# USB0_COMMON_0_VBP2APB_WRAP_CONTROLLER_VBP_CORE_ADDR_MAP register map
Vendor: Texas Instruments
Registers are 32-bit, access per field, reset 0x0 unless marked. A register's access mark holds for its fields unless they carry their own. Offsets are as the file gives them; [hi:lo] are bit positions; {n}, {i} and the like mark numbered series; 'fields as' and 'values as' point back to an identical list.

## USB0_COMMON_0_VBP2APB_WRAP_CONTROLLER_VBP_CORE_ADDR_MAP (part 8 of 8)
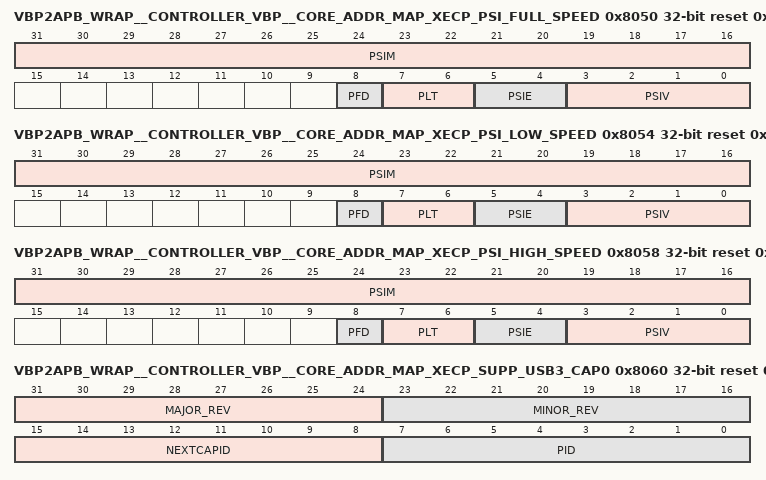
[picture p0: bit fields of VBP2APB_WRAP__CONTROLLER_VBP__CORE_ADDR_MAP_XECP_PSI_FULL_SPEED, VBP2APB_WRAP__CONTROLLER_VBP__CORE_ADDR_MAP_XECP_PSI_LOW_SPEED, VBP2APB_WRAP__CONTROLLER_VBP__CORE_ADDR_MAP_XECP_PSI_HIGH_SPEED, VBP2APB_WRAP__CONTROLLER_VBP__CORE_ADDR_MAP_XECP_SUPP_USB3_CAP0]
0x8050 VBP2APB_WRAP__CONTROLLER_VBP__CORE_ADDR_MAP_XECP_PSI_FULL_SPEED ro reset 0xC0021
  [31:16] PSIM — Protocol Speed ID Mantissa. This field defines the mantissa that shall be applied to the PSIE when calculating the maximum bit rate represented by this PSI Dword.
  [8] PFD — PSI Full-duplex. If this bit is '1' the link is full-duplex, and if '0' the link is half-duplex.
  [7:6] PLT — PSI Type. This field identifies whether the PSI Dword defines a symmetric or asymmetric bit rate, and if asymmetric, then this field also indicates if this Dword defines the receive or transmit bit rate. Note that the Asymmetric PSI Dwords shall be paired, i.e. an Rx immediately followed by a Tx, and both Dwords shall define the same value for the PSIV. PLT Values and corresponding bit rate: 0: Symmetric [Single PSI Dword] 1: Reserved 2: Asymmetric Rx [Paired with Asymmetric Tx PSI Dword] 3: Asymmetric Tx [Immediately follows Rx Asymmetric PSI Dword].
  [5:4] PSIE — Protocol Speed ID Exponent. This field defines the base 10 exponent times 3, that shall be applied to the Protocol Speed ID Mantissa when calculating the maximum bit rate represented by this PSI Dword. PSIE Values and corresponding bit rates: 0: Bits per second 1: Kb/s 2: Mb/s 3: Gb/s .
  [3:0] PSIV — Protocol Speed ID Value. If a device is attached that operates at the bit rate defined by this PSI Dword, then the value of this field shall be reported in the Port Speed field of PORTSC register [5.4.8 of xHCI specification] of a compatible port. Note, the PSIV value of 0 is reserved and shall not be defined by a PSI.
0x8054 VBP2APB_WRAP__CONTROLLER_VBP__CORE_ADDR_MAP_XECP_PSI_LOW_SPEED ro reset 0x5DC0012
  [31:16] PSIM — Protocol Speed ID Mantissa. This field defines the mantissa that shall be applied to the PSIE when calculating the maximum bit rate represented by this PSI Dword.
  [8] PFD — PSI Full-duplex. If this bit is '1' the link is full-duplex, and if '0' the link is half-duplex.
  [7:6] PLT — PSI Type. This field identifies whether the PSI Dword defines a symmetric or asymmetric bit rate, and if asymmetric, then this field also indicates if this Dword defines the receive or transmit bit rate. Note that the Asymmetric PSI Dwords shall be paired, i.e. an Rx immediately followed by a Tx, and both Dwords shall define the same value for the PSIV. PLT Values and corresponding bit rate: 0: Symmetric Single [PSI Dword] 1: Reserved 2: Asymmetric Rx [Paired with Asymmetric Tx PSI Dword] 3: Asymmetric Tx [Immediately follows Rx Asymmetric PSI Dword].
  [5:4] PSIE — Protocol Speed ID Exponent. This field defines the base 10 exponent times 3, that shall be applied to the Protocol Speed ID Mantissa when calculating the maximum bit rate represented by this PSI Dword. PSIE Values and corresponding bit rates: 0: Bits per second 1: Kb/s 2: Mb/s 3: Gb/s .
  [3:0] PSIV — Protocol Speed ID Value. If a device is attached that operates at the bit rate defined by this PSI Dword, then the value of this field shall be reported in the Port Speed field of PORTSC register [5.4.8 of xHCI specification] of a compatible port. Note, the PSIV value of 0 is reserved and shall not be defined by a PSI.
0x8058 VBP2APB_WRAP__CONTROLLER_VBP__CORE_ADDR_MAP_XECP_PSI_HIGH_SPEED ro reset 0x1E00023
  fields as VBP2APB_WRAP__CONTROLLER_VBP__CORE_ADDR_MAP_XECP_PSI_LOW_SPEED
0x8060 VBP2APB_WRAP__CONTROLLER_VBP__CORE_ADDR_MAP_XECP_SUPP_USB3_CAP0 ro reset 0x3000802
  [31:24] MAJOR_REV — Major Specification Release Number in Binary-Coded Decimal [i.e.,version 3.x is 03h]. This field identifies the major release number component of the specification with which the xHC is compliant.
  [23:16] MINOR_REV — Minor Specification Release Number in Binary-Coded Decimal [i.e.,version x.10 is 10h]. This field identifies the minor release number component of the specification with which the xHC is compliant.
  [15:8] NEXTCAPID — This field indicates the location of the next capability with respect to the effective address of this capability. Refer to Table 142 of xHCI specification for more information on this field.
  [7:0] PID — Capability ID. The value identifies the capability as Supported Protocol.
0x8064 VBP2APB_WRAP__CONTROLLER_VBP__CORE_ADDR_MAP_XECP_SUPP_USB3_CAP1 ro reset 0x20425355
  [31:0] USB_STRING — Name String, RO. This field is a mnemonic name string that references the specification with which the xHC is compliant. Four ASCII characters may be defined. Allowed characters are: alphanumeric, space, and underscore. Alpha characters are case sensitive. Refer to section 7.2.2 of xHCI specification for defined values.
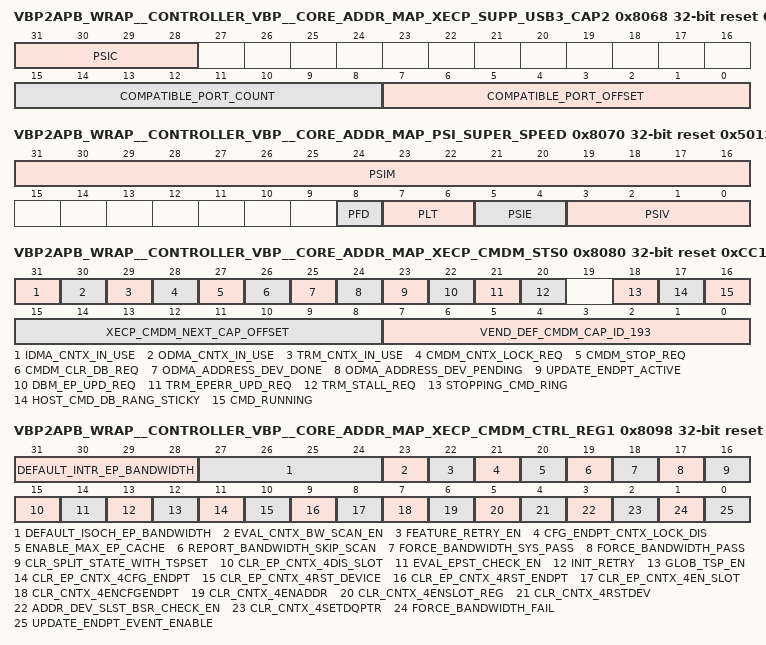
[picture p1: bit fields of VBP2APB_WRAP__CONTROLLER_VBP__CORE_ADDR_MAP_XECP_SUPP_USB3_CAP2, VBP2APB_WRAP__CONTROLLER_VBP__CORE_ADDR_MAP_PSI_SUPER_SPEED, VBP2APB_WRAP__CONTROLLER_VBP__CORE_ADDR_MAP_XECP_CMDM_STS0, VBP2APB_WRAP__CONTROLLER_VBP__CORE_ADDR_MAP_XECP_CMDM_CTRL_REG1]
0x8068 VBP2APB_WRAP__CONTROLLER_VBP__CORE_ADDR_MAP_XECP_SUPP_USB3_CAP2 ro reset 0x10000102
  [31:28] PSIC — Protocol Speed ID CountCount : 1, USB 3.0 Speed [Super Speed]. This field indicates the number of Protocol Speed ID [PSI] Dwords that the xHCI Supported Protocol Capability data structure contains. If this field is non-zero, then all speeds supported by the protocol shall be defined using PSI Dwords, i.e. no implied Speed ID mappings apply.
  [15:8] COMPATIBLE_PORT_COUNT — This field identifies the number of consecutive Root Hub Ports [starting at the Compatible Port Offset] that support this protocol. Valid values are 1 to MaxPorts.
  [7:0] COMPATIBLE_PORT_OFFSET — This field specifies the starting Port Number of Root Hub Ports that support this protocol. Valid values are 1 to MaxPorts.
0x806C VBP2APB_WRAP__CONTROLLER_VBP__CORE_ADDR_MAP_XECP_SUPP_USB3_PROTOCOL_SLOT_TYPE ro
  [4:0] PST — This field specifies the Protocol Slot Type value, which may be specified when allocating Device Slots that support this protocol. Valid values are 0 to 31. Refer to sections 4.6.3 and 7.2.2.1.4 of xHCI specification. The value of the Protocol Slot Type field declared by a xHCI Supported Protocol Capability structure is unique to an xHC implementation. Software shall not assume a fixed mapping of the Protocol Slot Type value to a specific type of Supported Protocol. Note that for compatibility reasons, the Protocol Slot Type value of 0 is the exception to this rule and reserved for the USB Protocol Device Slot type.
0x8070 VBP2APB_WRAP__CONTROLLER_VBP__CORE_ADDR_MAP_PSI_SUPER_SPEED ro reset 0x50134
  fields as VBP2APB_WRAP__CONTROLLER_VBP__CORE_ADDR_MAP_XECP_PSI_LOW_SPEED
0x8080 VBP2APB_WRAP__CONTROLLER_VBP__CORE_ADDR_MAP_XECP_CMDM_STS0 ro reset 0xCC1
  [31] IDMA_CNTX_IN_USE — Indicates that IDMA module currently owns the context access :
  [30] ODMA_CNTX_IN_USE — Indicates that ODMA module currently owns currently the context access
  [29] TRM_CNTX_IN_USE — Indicates that TRM modules owns the context access currently
  [28] CMDM_CNTX_LOCK_REQ — Indicates that Command Manager has requested a context lock.
  [27] CMDM_STOP_REQ — Indicates that Command Ring stop command is in progress.
  [26] CMDM_CLR_DB_REQ — Indicates that clearing an EP out of schedule is in progress.
  [25] ODMA_ADDRESS_DEV_DONE — Indicates that current address device command is done by ODMA.
  [24] ODMA_ADDRESS_DEV_PENDING — Indicates that ODMA has an address device command in progress.
  [23] UPDATE_ENDPT_ACTIVE — Indicates that updating of EP state is in progress
  [22] DBM_EP_UPD_REQ — Indicates that Doorbell Manager is issuing and EP update due to a doorbell ring on an EP that is in stop state
  [21] TRM_EPERR_UPD_REQ — Indicates that Transfer Ring Manager is issuing and EP update due to an EP error condition detected
  [20] TRM_STALL_REQ — Indicates that transfer ring manager is issuing and EP state update due to stall received
  [18] STOPPING_CMD_RING — Indicates that a STOP on the Command Ring is in progress
  [17] HOST_CMD_DB_RANG_STICKY — Indicates that command ring has a doorbell pending
  [16] CMD_RUNNING — Indicates that the command ring is running
  [15:8] XECP_CMDM_NEXT_CAP_OFFSET — Next capability offset
  [7:0] VEND_DEF_CMDM_CAP_ID_193 — Vendor defined capability ID. Command Ring Manager capability ID.
{0x8080+4i} VBP2APB_WRAP__CONTROLLER_VBP__CORE_ADDR_MAP_XECP_CMDM_RESERVED_{i} ro (i=1..5)
0x8098 VBP2APB_WRAP__CONTROLLER_VBP__CORE_ADDR_MAP_XECP_CMDM_CTRL_REG1 rw reset 0x3580AFFC
  [31:28] DEFAULT_INTR_EP_BANDWIDTH — Bandwidth calculation parameter: Default bandwidth for an Interrupt Endpoint.
  [27:24] DEFAULT_ISOCH_EP_BANDWIDTH — Bandwidth calculation parameter: Default bandwidth for an Isochronous Endpoint.
  [23] EVAL_CNTX_BW_SCAN_EN — Enable the Host Controller's Bandwidth checks for the Evaluate Context Command. Rescan the BW during evaluate context
  [22] FEATURE_RETRY_EN — Enable the EOB and NPKT==0 [called NYET condition for USB3] to be used to update a retry bit during stream switching operation. This is an internal safety feature. It should be treated as reserved bit.
  [21] CFG_ENDPT_CNTX_LOCK_DIS — Context lock mechanism to ensure command manager has exclusive access to internal context. This is a disable bit to allow software to turn off the context lock for configure endpoint command. This is a test/debug feature. '1': indicates disabled. '0': Indicates enabled
  [20] ENABLE_MAX_EP_CACHE
  [19] REPORT_BANDWIDTH_SKIP_SCAN
  [18] FORCE_BANDWIDTH_SYS_PASS
  [17] FORCE_BANDWIDTH_PASS
  [16] CLR_SPLIT_STATE_WITH_TSPSET — This bit allows engine to reset the split states when reset endpoint with TSP is posted. The split state is an internal context field in DMA engine. '0': Indicates that reset endpoint with TSP will preserve the split state. '1': Indicates that the reset endpoint with TSP will not preserve the split state.
  [15] CLR_EP_CNTX_4DIS_SLOT — '0': Disable clearing internal TRM and DMA context as well as the internal EP status signals during a disable slot command. '1': Enable clearing internal TRM and DMA context as well as the internal EP status signals during a disable slot command.
  [14] EVAL_EPST_CHECK_EN — '0': Disable evaluating the endpoint state during an Evaluate Context command, '1': Enable EP state check during an Evaluate Context command. If failed, context error will be returned.
  [13] INIT_RETRY — init_retry. Reserved to always read value of '1'.
  [12] GLOB_TSP_EN — '0': Disable the global context preservation. '1': Enable the internal context preservation for all commands that needs to preserve some of the internal context fields as a command with TSP would.
  [11] CLR_EP_CNTX_4CFG_ENDPT — '0': Disable clearing other internal EP status signals during a configure endpoint command. '1': Enable clearing other internal EP related status signals such as EP scheduled array, credit stored per EP, etc. during a configure endpoint command.
  [10] CLR_EP_CNTX_4RST_DEVICE — '0': Disable clearing other internal EP status signals during a reset device command. '1': Enable clearing other internal EP related status signals such as EP scheduled array, credit stored per EP, etc. during a reset device command.
  [9] CLR_EP_CNTX_4RST_ENDPT — '0': Disable clearing other internal EP status signals during a reset endpoint command. '1': Enable clearing other internal EP related status signals such as EP scheduled array, credit stored per EP. etc. during a reset endpoint command.
  [8] CLR_EP_CNTX_4EN_SLOT — '0': Disable clearing other internal EP status signals during an enable slot command. '1': Enable clearing other internal EP related status signals such as EP scheduled array, credit stored per EP. etc., during an enable slot command.
  [7] CLR_CNTX_4ENCFGENDPT — '0': Disable clearing internal TRM and DMA context during a configure endpoint command. '1': Enable clearing internal TRM and DMA context during a configure endpoint command.
  [6] CLR_CNTX_4ENADDR — '0': Disable clearing internal TRM and DMA context during an address device command. '1': Enable clearing internal TRM and DMA context during an address device command.
  [5] CLR_CNTX_4ENSLOT_REG — '0': Disable clearing internal TRM and DMA context during an enable slot command. '1': Enable clearing internal TRM and DMA context during an enable slot command.
  [4] CLR_CNTX_4RSTDEV — '0': Disable clearing internal TRM and DMA context during a reset device command. '1': Enable clearing internal TRM and DMA context during a reset device command.
  [3] ADDR_DEV_SLST_BSR_CHECK_EN — '0': Address device does not return the error for this condition. '1': Enable the EP state [default state] check with address device command with BSR. If failed, an event with context state error will be generated.
  [2] CLR_CNTX_4SETDQPTR — '0': Disable clearing internal TRM and DMA context during a set TR DQ pointer command. '1': Enable clearing internal TRM and DMA context during a set TR DQ pointer command.
  [1] FORCE_BANDWIDTH_FAIL — '0': Bandwidth calculation handled normally. '1': Forces a failure in the endpoint bandwidth calculation so that engine will reject a configure EP command.
  [0] UPDATE_ENDPT_EVENT_ENABLE — '0': Disable generation of the completion event. '1': Enable the command manager to generate a completion event after an EP state update due to internal error. This bit is for test debug.
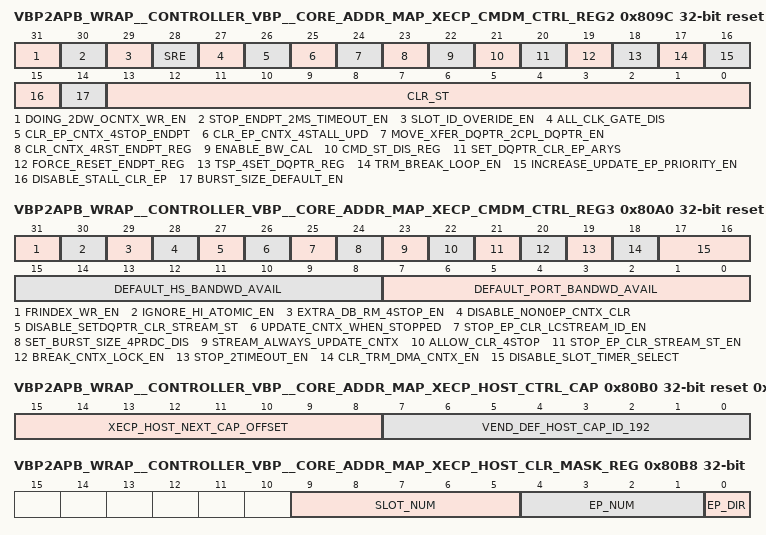
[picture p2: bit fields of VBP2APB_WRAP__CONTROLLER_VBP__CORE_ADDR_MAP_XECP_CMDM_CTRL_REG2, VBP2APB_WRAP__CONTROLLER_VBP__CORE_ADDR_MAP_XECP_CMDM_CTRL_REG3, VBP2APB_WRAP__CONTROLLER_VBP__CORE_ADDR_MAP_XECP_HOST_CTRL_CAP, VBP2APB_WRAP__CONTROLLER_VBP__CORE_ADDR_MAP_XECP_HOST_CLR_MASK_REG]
0x809C VBP2APB_WRAP__CONTROLLER_VBP__CORE_ADDR_MAP_XECP_CMDM_CTRL_REG2 rw reset 0x6C60000
  [31] DOING_2DW_OCNTX_WR_EN — Enable only to update the EP state to output context on every EP output context update condition. This is to allow to have a control over either update the entire EPoutput context field or only update the first two DWORDs. '0': update the entire output context field. '1': update only 2 DWORDs
  [30] STOP_ENDPT_2MS_TIMEOUT_EN — Enable a delay to stop endpoint command that is executed in XFER engine. '0': XFER engine will not wait. '1': XFER engine will always wait for 2 ms before it checks whether an EP transfer ring is at a stop of packet boundary
  [29] SLOT_ID_OVERIDE_EN — Force '0' on slot ID when a command transfer event is generated. '0': not forced, '1': Forced to 0.
  [28] SRE — Force and error on save command always. '0': do not force, '1': always force return save error.
  [27] ALL_CLK_GATE_DIS — '0': Turn ON the TTE clock. '1': Turn OFF the TTE clock.
  [26] CLR_EP_CNTX_4STOP_ENDPT — '0': Disable clearing other internal per EP status signal during a stop endpoint command. '1': Enable clearing other internal per EP status signal during a stop endpoint command.
  [25] CLR_EP_CNTX_4STALL_UPD — '0': Disable clearing other internal EP status signal during stall handling. '1': Enable clearing other internal EP status signal during stall handling.
  [24] MOVE_XFER_DQPTR_2CPL_DQPTR_EN — '0': The internal context write DQ pointer moved to internal read pointer during reset EP command. '1': The write DQ pointer stays as it was during reset endpoint command.
  [23] CLR_CNTX_4RST_ENDPT_REG — '0': Disable clearing internal TRM and DMA context during a reset endpoint command. '1': Enable clearing internal TRM and DMA context during a reset endpoint command.
  [22] ENABLE_BW_CAL — '0': Disable hardware bandwidth calculations. '1': Enable hardware bandwidth calculations.
  [21] CMD_ST_DIS_REG — '0': Delay processing command ring TRB while internal context requests are pending. '1': Process command ring TRBs normally.
  [20] SET_DQPTR_CLR_EP_ARYS — '0': Disable clearing other internal EP status signals during a set DQ pointer command. '1': Enable clearing other internal EP status signals during a set DQ pointer command.
  [19] FORCE_RESET_ENDPT_REG — '0': Check the slot and endpoint state prior to processing a reset endpoint command. '1': Ignore the slot and endpoint state when processing a reset endpoint command.
  [18] TSP_4SET_DQPTR_REG — '0': Disable sequence number preservation during set DQ pointer command. '1': Enable sequence number to be preserved during set DQ pointer command.
  [17] TRM_BREAK_LOOP_EN — trm_break_loop_en. This is an internal safeguard register. It enables a different mechanism of handling stop endpoint command. It should be treated as a reserved field. The default should not be alternate unless specific purpose. '0': Disable. '1': Enable.
  [16] INCREASE_UPDATE_EP_PRIORITY_EN — Increase Update EP priority over commands in the command ring to avoid prolonging STALL handling. '0': Pending commands have a higher priority than update endpoint processing. '1': Update endpoint processing in the command manager has a higher priority than pending commands. Note: Enabling this bit can prevent prolonged stall handling.
  [15] DISABLE_STALL_CLR_EP — '0': Stall handling does clear the internal EP status signals. '1': Disable the clear function when stall response received.
  [14] BURST_SIZE_DEFAULT_EN — When context is first initialized, it is assumed one remote NPKT. It is also assumed that max burst size as remote NPKT. This bit enables to assume max burst size as remote NPKT. '0': Assume 1 NPKT. '1': Assume max burst size as NPKT.
  [13:0] CLR_ST — Clear state machine present state: Setting a specified bit to '1', will reset the corresponding command manager state machine to the starting/idle state. bit-0: disable slot state machine. bit-1: enable slot state machine. bit-2: reset endpoint state machine. bit-3: reset device state machine. bit-4: command ring state machine. bit-5: stop endpoint state machine. bit-6: set dq pointer state machine. bit-7: force header state machine. bit-8: evaluate context state machine. bit-9: update endpoint state machine. bit-10: address device state machine. bit-11: port bandwidth state machine. bit-12: read output context state machine. bit-13: configure endpoint state machine.
0x80A0 VBP2APB_WRAP__CONTROLLER_VBP__CORE_ADDR_MAP_XECP_CMDM_CTRL_REG3 rw reset 0x2220505A
  [31] FRINDEX_WR_EN — MFIndex register write enable. For debug purposes.
  [30] IGNORE_HI_ATOMIC_EN
  [29] EXTRA_DB_RM_4STOP_EN
  [28] DISABLE_NON0EP_CNTX_CLR
  [27] DISABLE_SETDQPTR_CLR_STREAM_ST — disable_setdqptr_clr_stream_st. Disable setTRDQPtr from clearing the current stream state.
  [26] UPDATE_CNTX_WHEN_STOPPED — update_cntx_when_stopped. Allow setTRDQPtr cmd to update the local context anytime the EP is not running [otherwise checks CSTREAMID].
  [25] STOP_EP_CLR_LCSTREAM_ID_EN — stop_ep_clr_lcstream_id_en. Enable stop endpoint command to return stream st to disabled [0] in EP context.
  [24] SET_BURST_SIZE_4PRDC_DIS
  [23] STREAM_ALWAYS_UPDATE_CNTX
  [22] ALLOW_CLR_4STOP
  [21] STOP_EP_CLR_STREAM_ST_EN — stop_ep_clr_stream_st_en. Enable stop endpoint command to return stream st to disabled [0] in EP context.
  [20] BREAK_CNTX_LOCK_EN
  [19] STOP_2TIMEOUT_EN — stop_2timeout_en. Stop transaction timeout.
  [18] CLR_TRM_DMA_CNTX_EN
  [17:16] DISABLE_SLOT_TIMER_SELECT — These two bits specify the delay that we can have for disable slot state to be completed. We can delay the generation of the command transfer event during disable slot command. Possible values: '00': delay is disabled, '01': 100us delay, '10': 8ms delay, '11': 10ms delay.
  [15:8] DEFAULT_HS_BANDWD_AVAIL — The default available bandwidth to advertise on each HS port in 10 0ncrements [80%]. Bandwidth Calculation is a reserved field for PPT.
  [7:0] DEFAULT_PORT_BANDWD_AVAIL — The default available bandwidth to advertise on each LS, FS, SS port in 10 0ncrements [90%]. Bandwidth calculation is a reserved field for PPT.
0x80B0 VBP2APB_WRAP__CONTROLLER_VBP__CORE_ADDR_MAP_XECP_HOST_CTRL_CAP ro reset 0xB0C0
  [15:8] XECP_HOST_NEXT_CAP_OFFSET — Next xHCI Extended Capability Pointer. This field points to the xHC MMIO space offset of the next xHCI extended capability pointer. A value of 00h indicates the end of the extended capability list. A non-zero value in this register indicates a relative offset, in Dwords, from this Dword to the beginning of the next extended capability. For example, assuming an effective address of this data structure is 350h and assuming a pointer value of 068h, we can calculate the following effective address: 350h + [068h shifted left 2] -> 350h + 1A0h -> 4F0h
  [7:0] VEND_DEF_HOST_CAP_ID_192 — Capability ID. This field identifies the xHCI Extended capability. 192-255 are IDs available for vendor specific extensions to the xHCI.
0x80B4 VBP2APB_WRAP__CONTROLLER_VBP__CORE_ADDR_MAP_XECP_HOST_CTRL_RSVD ro
0x80B8 VBP2APB_WRAP__CONTROLLER_VBP__CORE_ADDR_MAP_XECP_HOST_CLR_MASK_REG
  [9:5] SLOT_NUM wo — Slot number.
  [4:1] EP_NUM wo — Endpoint number
  [0] EP_DIR wo — Indicates the direction of the Endpoint
0x80BC VBP2APB_WRAP__CONTROLLER_VBP__CORE_ADDR_MAP_XECP_HOST_CLR_IN_EP_VALID_REG wo
  [31:0] PORT_NUM — This field indicates the port number.
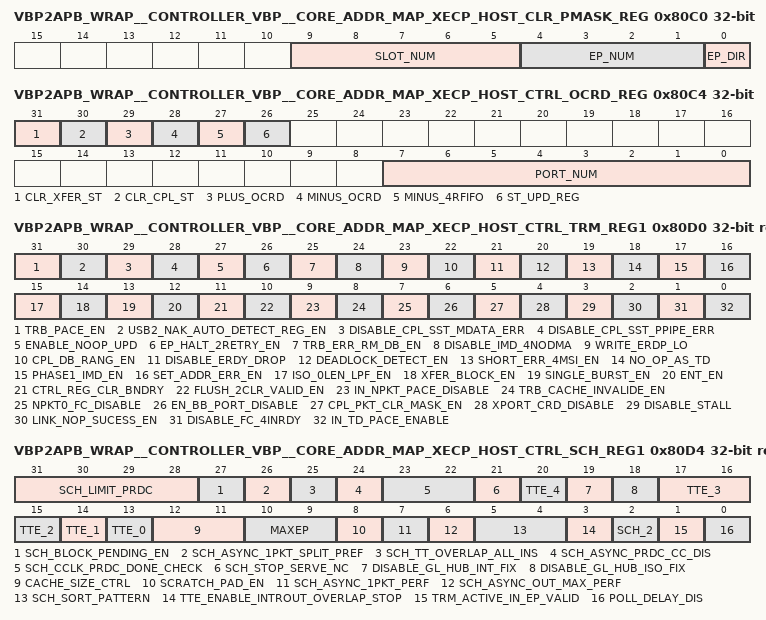
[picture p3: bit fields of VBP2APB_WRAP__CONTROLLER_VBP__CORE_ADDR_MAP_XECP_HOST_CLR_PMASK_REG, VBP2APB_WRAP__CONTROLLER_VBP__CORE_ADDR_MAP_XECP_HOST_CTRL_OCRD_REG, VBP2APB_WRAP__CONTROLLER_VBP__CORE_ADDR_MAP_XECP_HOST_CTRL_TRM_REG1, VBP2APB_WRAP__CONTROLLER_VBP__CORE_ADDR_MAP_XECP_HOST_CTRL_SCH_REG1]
0x80C0 VBP2APB_WRAP__CONTROLLER_VBP__CORE_ADDR_MAP_XECP_HOST_CLR_PMASK_REG
  [9:5] SLOT_NUM wo — Slot number
  [4:1] EP_NUM wo — Endpoint number
  [0] EP_DIR wo — Indicates the direction of the Endpoint
0x80C4 VBP2APB_WRAP__CONTROLLER_VBP__CORE_ADDR_MAP_XECP_HOST_CTRL_OCRD_REG
  [31] CLR_XFER_ST wo — Write '1' to force XFER state return to IDLE
  [30] CLR_CPL_ST wo — Write '1' to force CPL state return to IDLE
  [29] PLUS_OCRD wo — Add one credit to a port
  [28] MINUS_OCRD wo — Subtract one credit from a port
  [27] MINUS_4RFIFO wo — Indicates whether the subtract command operates on TX FIFO credit or RX FIFO credit.
  [26] ST_UPD_REG ro — Slot state control. st_upd_reg
  [7:0] PORT_NUM wo — port number
0x80C8 VBP2APB_WRAP__CONTROLLER_VBP__CORE_ADDR_MAP_XECP_HOST_CTRL_TEST_BUS_LO ro
  [31:0] TEST_BUS_LO — Host controller test bus low 32-bits.
0x80CC VBP2APB_WRAP__CONTROLLER_VBP__CORE_ADDR_MAP_XECP_HOST_CTRL_TEST_BUS_HI ro
  [31:0] TEST_BUS_HI — Host controller test bus high 32-bits.
0x80D0 VBP2APB_WRAP__CONTROLLER_VBP__CORE_ADDR_MAP_XECP_HOST_CTRL_TRM_REG1 rw reset 0x4E1BD105
  [31] TRB_PACE_EN — Must be set to '0'.
  [30] USB2_NAK_AUTO_DETECT_REG_EN — '0': Disables a special function which detects NAK received and goes into a single packet pace mode so that we do not burst ahead. '1': Enables a special function which detects NAK received and goes into a single packet pace mode so that we do not burst ahead.
  [29] DISABLE_CPL_SST_MDATA_ERR — '0': Enable the error check. '1': Disable the error check for Data Move stream state. It will generate a transfer event with prime PIPE error completion code if an error is detected.
  [28] DISABLE_CPL_SST_PPIPE_ERR — '0': Enable the error check, '1': Disable the error check for prime PIPE stream state. It will generate a transfer event with prime PIPE error completion code if an error is detected.
  [27] ENABLE_NOOP_UPD — This bit has been modified for its usage since PPT A0. It is used to allow NO-OP TRB to be treated in a same way as link TRB. In other words, it will update the internal context when it is fetched while the internal context cache TRB FIFO is empty. '0': Disable the function, '1': Enable the cache function.
  [26] EP_HALT_2RETRY_EN — This is a special internal condition enable for CPL engine which it enables all EP halt conditions detected to cause the proper actions in a response. '0': Disabled, '1': Enabled. Note: Only default condition of '1' is valid.
  [25] TRB_ERR_RM_DB_EN — This is a special internal branch condition control in XFER engine which does the EP transfer ring process. When this bit is set a retry condition identified by completion engine will cause XFER engine to stop what it is currently in progress and start over from IDLE state. '0': Disable, '1': Enable the branch condition.
  [24] DISABLE_IMD_4NODMA — This is a special internal branch condition control in XFER engine which does the EP transfer ring process. When this bit is set, the XFER will not continue even if the next TRB is identified as a non DMA TRB. The engine will then wait for the next scheduled request for this EP. '0': Disable, '1': Enable the branch condition.
  [23] WRITE_ERDP_LO — When ERDP register is updated by software, it is expected as an atomic function since this is a 64-bit register. It is expected, that the ERDP [64-bit register] is updated together when ERDP high 32 is written. We have this bit designed to ignore the atomic operation required from software for ERDP low 32 bits. When this bit is set to '1', it will update the ERDP low 32 bits when software issues a CPU write to the ERDP low 32 bits. '0': not ignore, '1': ignore atomic operation.
  [22] CPL_DB_RANG_EN — Setting this bit to '1' will force an internal doorbell ring on the EP that it has received a response.
  [21] DISABLE_ERDY_DROP — '0': Drop ERDYs received when not in a flow control state. '1': Do not drop ERDYs received when not in a flow control state. Note: We typically drop unexpected ERDY
  [20] DEADLOCK_DETECT_EN — '0': Disable timeout of TRB error processing. '1': Enable timeout of a TRB processing in few critical states that possibly have a deadlock for unexpected reason. A vendor defined completion code is generated in the event of a timeout during TRB processing.
  [19] SHORT_ERR_4MSI_EN — This bit is modified to enable a feature where we can control whether or not to report an event with completion code of Missed Service Error when a short packet response has been received not in the expected service interval. '0': Disable this function so that the xHC engine will report an event with completion code of Short packet indication and another event with MSE at the end of the TD, '1': Enables all completion event that supposedly is short to the MSE.
  [18] NO_OP_AS_TD — This bit is modified to enable the NO_OP TRB as a TD when Missing Service Interval Error has encountered. This is only for PPT B0, LPT and CB. '0': disable, '1': enable.
  [17] PHASE1_IMD_EN — Enable a special branch condition of the XFER ring process state. This is to ensure that we have a DMA request issued to DMA engine during a PHASE1 process of the TTE. '0': disabled, '1': enabled
  [16] SET_ADDR_ERR_EN — '0': Disable error reporting if a SETUP TRB contains the following: bRequest = SET_ADDRES, bmRequestType = [DTD] Host-to-device, Type = Standard, Recipient = Device. '1': Enable error reporting for this case.
  [15] ISO_0LEN_LPF_EN — Enables a special internal state branch condition for periodic EP during its transfer ring process. If we have identified that the next TRB is a non DMAnable TRB such as LINK TRB, or Event data TRB, then this bit enables XFER engine to continue process the next TRB as if the ENT bit of the TRB is set. '0': disable, '1': enable.
  [14] XFER_BLOCK_EN — Not used. XFER engine has a new function that provides a support to ISO EP within a long PCIe delayed system. The long delay can cause missing service interval while pending response has not all been returned. This bit enables engine to identify a MSI condition and store the context bit for a pending response so that we can process a MSI event when pending response received. '0': disable this function, '1': enable this function.
  [13] SINGLE_BURST_EN — '0': Bulk and interrupt endpoints use burst size defined by endpoint context. '1: Force the Bulk and Interrupt endpoints to use a burst size of 1.
  [12] ENT_EN — '0': ENT bit is ignored. '1': ENT bit is processed. The transfer engine will service the next TRB.
  [11] CTRL_REG_CLR_BNDRY — Setting this bit to '1' will force the transfer engine to set the packet boundary flag. This flag is an important flag, which may cause a deadlock. This is a safety feature that we have plugged in.
  [10] FLUSH_2CLR_VALID_EN — This bit is modified to support PPTB0, LPT and CP for a feature that we will clear the single IN EP array based on ISO flush or short flush. '0': Indicate that we do not need to clear IN EP array based on flush conditions. '1': indicate that we do clear IN EP array based on flush conditions
  [9] IN_NPKT_PACE_DISABLE — Setting this bit to '1' will force the transfer engine state machine to exit the CPL_WAIT state. This is designed to avoid unexpected deadlock in CPL_WAIT state.
  [8] TRB_CACHE_INVALIDE_EN — '0': Disable internal TRB cache invalidation. '1': Enable internal TRB cache invalidation auto detect function. This will allow engine to handle more than 4 TRBs per packet.
  [7] NPKT0_FC_DISABLE — '0': USB3 responses with NumPkts equal to 0 will be treated as a flow control condition. '1': USB3 responses with NumPkts equal to 0 will not be treated as a flow control condition.
  [6] EN_BB_PORT_DISABLE — '0': Babble errors will not disable the port. '1': Babble errors will disable the auto detect function This will allow engine to handle more than 4 TRBs per packet.
  [5] CPL_PKT_CLR_MASK_EN — Enable a function, which clears a mask of an EP on any response of that EP. '0': Clear the scheduler mask normally, '1': Clear the scheduler mask on each received packet.
  [4] XPORT_CRD_DISABLE — This bit is designed to allow XFER engine to do a transfer without checking against the available port credit. '0': Advertises accurate buffer credit information to the scheduler. '1': Advertises non-zero buffer credits to the scheduler [e.g. never backpressure back on buffer credit information]
  [3] DISABLE_STALL — '0': Process stalls reported by the DMA engine. '1': Ignore stall response received reported by the DMA engine.
  [2] LINK_NOP_SUCESS_EN — '0': Process transaction errors due to CERR count reached or transaction timeout reported by the DMA engine. '1': Ignore transaction errors reported by the DMA engine.
  [1] DISABLE_FC_4INRDY — '0': Obey the NPKT0 and EOB flow control. '1': Ignore received flow control for implied NRDY [e.g EOB or NPKT=0] for USB3 only
  [0] IN_TD_PACE_ENABLE — '0': Disable TD pacing for IN endpoint. '1': Enable TD pacing for IN endpoints.
0x80D4 VBP2APB_WRAP__CONTROLLER_VBP__CORE_ADDR_MAP_XECP_HOST_CTRL_SCH_REG1 rw reset 0x8100
  [31:28] SCH_LIMIT_PRDC — Host Control Scheduler: sch_limit_prdc
  [27] SCH_BLOCK_PENDING_EN — Host Control Scheduler: sch_block_pending_en
  [26] SCH_ASYNC_1PKT_SPLIT_PREF — Host Control Scheduler: sch_async_1pkt_split_pref
  [25] SCH_TT_OVERLAP_ALL_INS — Host Control Scheduler: sch_tt_overlap_all_ins
  [24] SCH_ASYNC_PRDC_CC_DIS — Host Control Scheduler: sch_async_prdc_cc_dis
  [23:22] SCH_CCLK_PRDC_DONE_CHECK — Host Control Scheduler: sch_cclk_prdc_done_check
  [21] SCH_STOP_SERVE_NC — Host Control Scheduler: Enable Stop serving packets to disabled port
  [20] TTE_4 — TTE: Reserved
  [19] DISABLE_GL_HUB_INT_FIX — TTE: disable_gl_hub_int_fix
  [18] DISABLE_GL_HUB_ISO_FIX — TTE: disable_gl_hub_iso_fix
  [17:16] TTE_3 — TTE: Reserved
  [15] TTE_2 — TTE: Disable split error request to TRM on unserved interrupt-INs
  [14] TTE_1 — TTE: Disable checking of missed microframes
  [13] TTE_0 — TTE: Disable interrupt complete split limit to 3 micro frames
  [12:11] CACHE_SIZE_CTRL — Command Manager: Context cache enable
  [10:9] MAXEP — Command Manager: Allow dynamically setting different max EP allowed. The max EP supported scales with the scratch pad size. This allows driver to allocate small memory sizes if it needed. 0: 32 EPs, 1: 16 EPs, 2: 8 EPs, 3: 4 EPs.
  [8] SCRATCH_PAD_EN — Command Manager: Enables scratch pad function
  [7] SCH_ASYNC_1PKT_PERF — Host Control Scheduler: Disable burst limit '1' for async in presence of another port periodic packets.
  [6] SCH_ASYNC_OUT_MAX_PERF — Host Control Scheduler: Enable maximal out performance [may cause unfairness or short term starvation].
  [5:4] SCH_SORT_PATTERN — Host Control Scheduler: Search priority. Possible values: '00': Sort by Interval then ISO over interrupt, '01','10','11': Experimental sort algorithms.
  [3] TTE_ENABLE_INTROUT_OVERLAP_STOP — Host Control Scheduler: tte_enable_introut_overlap_stop
  [2] SCH_2 — Host Control Scheduler: Disable TTE IN overlap
  [1] TRM_ACTIVE_IN_EP_VALID — Host Control Scheduler: Disable TRM active IN EP valid check function
  [0] POLL_DELAY_DIS — Host Control Scheduler: Disable poll delay function
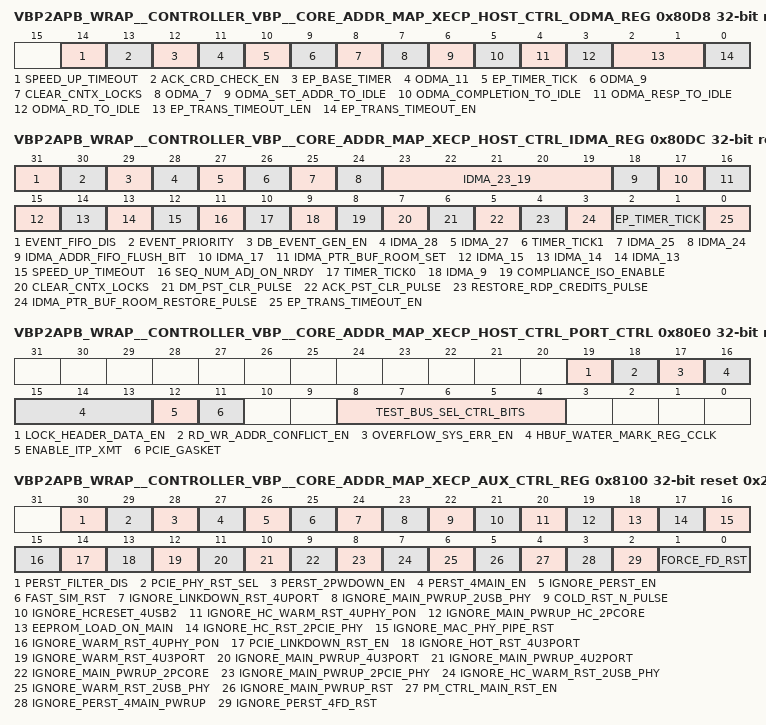
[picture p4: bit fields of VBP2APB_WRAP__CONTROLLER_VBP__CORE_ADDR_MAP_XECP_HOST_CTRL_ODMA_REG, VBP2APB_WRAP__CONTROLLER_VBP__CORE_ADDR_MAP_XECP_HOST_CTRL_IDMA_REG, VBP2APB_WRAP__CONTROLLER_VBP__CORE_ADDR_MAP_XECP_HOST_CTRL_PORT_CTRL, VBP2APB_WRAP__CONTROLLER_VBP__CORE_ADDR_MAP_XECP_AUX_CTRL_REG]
0x80D8 VBP2APB_WRAP__CONTROLLER_VBP__CORE_ADDR_MAP_XECP_HOST_CTRL_ODMA_REG rw reset 0x14003002
  [14] SPEED_UP_TIMEOUT — '0': Disable the speed up transaction timeout function. '1': Enable the transaction timeout speed up based on no-connect detected on a particular port
  [13] ACK_CRD_CHECK_EN — '0': Disable the ACK credit check function '1': Enable the ACK credit check function that ODMA provides
  [12] EP_BASE_TIMER — '0': Employs a 1us EP Transaction Base Timer. Enables a Timeout range from 16us to 64us '1': Employs a 125us EP Transaction Base Timer. Enables a Timeout range from 2ms to 8ms
  [11] ODMA_11 — Setting this field will prohibit the Set Address Finite State Machine Credit Handshake with TTE Logic
  [10] EP_TIMER_TICK — Setting this field will disable the EP Transaction Timer function when the Command Manager is performing a Stop Endpoint Command or when the LTSSM is in Recovery
  [9] ODMA_9 — Setting this field prohibits the Set Address Finite State Machine from being flow controlled when an ACK with NPKT=0 is received in response to the SETUP DP initiated during SET_ADDRESS
  [8] CLEAR_CNTX_LOCKS — Setting this field generates a pulse that clears the ownership of the context semaphore that is shared between the Out DMA Response and Completion Finite State Machines
  [7] ODMA_7 — Setting this field generates a pulse that implicitly returns all of the Out DMA ACK credits on all ports
  [6] ODMA_SET_ADDR_TO_IDLE — Setting this field generates a pulse that returns the Out DMA Set Address Finite State Machine into the IDLE state
  [5] ODMA_COMPLETION_TO_IDLE — Setting this field generates a pulse that returns the Out DMA Completion Finite State Machine into the IDLE state
  [4] ODMA_RESP_TO_IDLE — Setting this field generates a pulse that returns the Out DMA Response Finite State Machine into the IDLE state.
  [3] ODMA_RD_TO_IDLE — Setting this field generates a pulse that returns the Out DMA Read Finite State Machine into the IDLE state.
  [2:1] EP_TRANS_TIMEOUT_LEN — Controls the duration of the EP Transaction Timeout [depends on the settings of EP Transaction Base Timer [bit[12]]]. Possible values: 0: 64us [[12]=0] or 8ms [[12]=1] EP Transaction Timeout, 1: 32us [[12]=0] or 4ms [[12]=1] EP Transaction Timeout, 2: 16us [[12]=0] or 2ms [[12]=1] EP Transaction Timeout, 3: EP Transaction Timer is DISABLED.
  [0] EP_TRANS_TIMEOUT_EN — '0': Enables the EP Transaction Timeout Function, '1': Disables the EP Transaction Timeout Function
0x80DC VBP2APB_WRAP__CONTROLLER_VBP__CORE_ADDR_MAP_XECP_HOST_CTRL_IDMA_REG rw reset 0x402
  [31] EVENT_FIFO_DIS — Used in Event Manager. '0': Enable single ring optimization, '1': Disable single ring optimization.
  [30] EVENT_PRIORITY — Used in Event Manager. '0': CPL Engine priority over XFER Manager, '1': XFER Manager priority over CPL Engine.
  [29] DB_EVENT_GEN_EN — Used in Doorbell Manager. '0': Do not generate an event. '1': Enable an event generated with completion code TRB_CMPL_ENDPOINT_NOT_ENABLED_ERR when a doorbell ring on an EP, which has not running or stop state.
  [28] IDMA_28 — '0': Drop Deferred Ack/Ack TPs. [default] [Bug #5481], '1': Allow Deferred Ack/Ack TPs.
  [27] IDMA_27 — '0': Drop Deferred Stream Reject TPs. [default] [Bug #5434], '1': Allow Deferred Stream Reject TPs.
  [26] TIMER_TICK1 — Allows to select the EP Timer Tick to be either the 1us timer tick or the 125us timer tick or the 1ms timer tick or the 4ms timer tick based on the setting of this bit and bit 10 of this register. The encoding is as follows [bit{[26],[10]}]: '00' : 1us EP Timer Tick, '01' : 125us EP Timer Tick, '10' : 1ms EP Timer Tick, '11' : 4ms EP Timer Tick.
  [25] IDMA_25 — Flush TTE Address FIFO
  [24] IDMA_24 — '0': Flush an Async Address FIFO, '1': Flush a Periodic Address FIFO.
  [23:19] IDMA_23_19 — Port Number of Address FIFO to Flush.
  [18] IDMA_ADDR_FIFO_FLUSH_BIT — Flush IDMA Address FIFO strobe.
  [17] IDMA_17 — '0': All ACK ACKs are put in the Periodic Header FIFO in XPPE, '1': Only Periodic ACK ACKs are put in the Periodic Header FIFO in XPPE.
  [16] IDMA_PTR_BUF_ROOM_SET — '0': Default IDMA Pointer Buffer Room to 8 : Requires strobe of host_ctrl_idma_reg[3][idma_ptr_buf_room_restore_pulse] to take effect, '1': Default IDMA Pointer Buffer Room to 4 : Requires strobe of host_ctrl_idma_reg[3][idma_ptr_buf_room_restore_pulse] to take effect.
  [15] IDMA_15 — Disable drop spurious DP when i_npkt==0
  [14] IDMA_14 — Disable drop spurious DP when EP is in flow conrtrol.
  [13] IDMA_13 — Disable dropping all deferred packets on ISO Endpoints.
  [12] SPEED_UP_TIMEOUT — '0': Disable the speed up transaction timeout function. '1': Enable the transaction timeout speed up based on no-connect detected on a particular port
  [11] SEQ_NUM_ADJ_ON_NRDY — '0': Enable sequence number adjustment on NRDY received for USB3 when we are expecting a response. '1': Enable sequence number adjustment on any NRDY received for USB3.
  [10] TIMER_TICK0 — '0': Employs a 1us EP Transaction Base Timer. Enables a Timeout range from 16us to 64us. '1': Employs a 125us EP Transaction Base Timer. Enables a Timeout range from 2ms to 8ms.
  [9] IDMA_9 — Setting this field will disable the EP Transaction Timer function when the Command Manager is performing a Stop Endpoint Command or when the LTSSM is in Recovery
  [8] COMPLIANCE_ISO_ENABLE — Setting this field enables the Compliance Isochronous mode of operation. It bounds the upper limit on the NPKT field for all ISO Acknowledgments generated from the Host to the value of 2.
  [7] CLEAR_CNTX_LOCKS — Setting this field generates a pulse that clears the ownership of the context semaphore that is shared between the IN DMA Acknowledge and Data Mover Finite State Machines
  [6] DM_PST_CLR_PULSE — Setting this field generates a pulse that returns the IN DMA Data Mover Finite State Machine into the IDLE state
  [5] ACK_PST_CLR_PULSE — Setting this field generates a pulse that returns the IN DMA Acknowledge Finite State Machine into the IDLE state.
  [4] RESTORE_RDP_CREDITS_PULSE — Setting this field generates a pulse that implicitly returns all of the IN DMA Data Packet credits on all ports.
  [3] IDMA_PTR_BUF_ROOM_RESTORE_PULSE — Setting this field generates a pulse that clears all the Read and Write Pointers associated with the various DMA Address FIFOs causing them to appear empty
  [2:1] EP_TIMER_TICK — '00': 1us/125us/1ms/4ms EP Timer Tick '01': 2us/250us/2ms/8ms EP Timer Tick '10': 4us/500us/4ms/16ms EP Timer Tick '11': Disabled EP Timer Tick
  [0] EP_TRANS_TIMEOUT_EN — '0': Enables the EP Transaction Timeout Function, '1': Disables the EP Transaction Timeout Function.
0x80E0 VBP2APB_WRAP__CONTROLLER_VBP__CORE_ADDR_MAP_XECP_HOST_CTRL_PORT_CTRL reset 0x780F
  [19] LOCK_HEADER_DATA_EN rw
  [18] RD_WR_ADDR_CONFLICT_EN rw
  [17] OVERFLOW_SYS_ERR_EN rw — '0': Disable error generation. '1': Enable to generate a host system error when receive buffer overflow on any ports.
  [16:13] HBUF_WATER_MARK_REG_CCLK rw — This 4-bit register is designed as a water mark for when to turn on link FC credit return disable. This is used in xhc_prot_rppe.v for receive buffer management. We have 8 header credit in per port receive buffer. When buffer received enough packets, it will need to disable the link credit FC return in order to balance the processing delay within DMA engine. 0: Always enable link credit FC return, 1-8: Water mark value.
  [12] ENABLE_ITP_XMT rw — Bit[s] of this field are designated to individually control each USB3 port to enable ITP transmission. 0: Do not Transmit any ITP. 1: Transmit ITP
  [11] PCIE_GASKET rw — Reserved to '1'. Note: An internal register bit for PCIe gasket. It is only valid for value of '1'
  [8:4] TEST_BUS_SEL_CTRL_BITS rw — Test bus select control bits. 0: Clock, Reset and Power management Debug bus 1: PCIe PIPE Bus, 2: USB3 PIPE Bus, 3: USB2 UTMI Bus, 4: TRM Debug Bus, 5: Scheduler Debug Bus, 6: ODMA Debug Bus, 7: IDMA Debug Bus.
0x8100 VBP2APB_WRAP__CONTROLLER_VBP__CORE_ADDR_MAP_XECP_AUX_CTRL_REG reset 0x2917C0F4
  [30] PERST_FILTER_DIS rw — reserved. perst_filter_dis This field should not be modified by software.
  [29] PCIE_PHY_RST_SEL rw — This bit enables AUX reset control module to assert the pcie_phy_reset either from PIPE reset or from Aux power up reset only. The pcie_phy_reset is an internal signal for CB PHY only. '0': Aux PowerUp Reset, '1': PIPE PHY reset This field should not be modified by software.
  [28] PERST_2PWDOWN_EN rw — This bit enables the AUX PM control module to assert mac_phy_powerdown state to P1 as soon as PERST# is deasserted. If disabled, then the AUX PM control state will follow its nature cause to determine the power down states for PIPE. '0': disabled, '1': enabled. This field should not be modified by software.
  [27] PERST_4MAIN_EN rw — This bit enables the internal reset control module to immediately start a reset assertion process when PERST# is deasserted without waiting for PCIe device is out of D3 state. This is for warm reboot only. The PERST# can still have impact as a reset if the xHC is in D3 and allow PERST# as a powerup reset bit set. '0: disabled '1: enabled PERST# as an immediately reset This field should not be modified by software.
  [26] IGNORE_PERST_EN rw — This bit disables the PERST# to cause an internal reset. '0: enable '1: disable the PERST# This field should not be modified by software.
  [25] FAST_SIM_RST rw — This bit enables a speed up function or AUX reset at startup. Normally we wait for 20ms after AUX power level has reached. When in speed up mode, we wait only around 3-4us. '0: Disabled, '1: Enabled for fast sim. This field should not be modified by software.
  [24] IGNORE_LINKDOWN_RST_4UPORT rw — When set to '1' ignore a port reset that is caused by a USB port link went down. This field should not be modified by software.
  [23] IGNORE_MAIN_PWRUP_2USB_PHY rw — When set to '1' ignore main powerup reset to USB PHY PIPE reset This field should not be modified by software.
  [22] COLD_RST_N_PULSE rw — When set to '1' allow software to fire a cold reset to USB port logic This field should not be modified by software.
  [21] IGNORE_HCRESET_4USB2 rw — When set to '1' ignore HC reset to reset the USB2 Port logic This field should not be modified by software.
  [20] IGNORE_HC_WARM_RST_4UPHY_PON rw — When set to '1' ignore HC reset to the USB PHY power-on reset This field should not be modified by software.
  [19] IGNORE_MAIN_PWRUP_HC_2PCORE rw — When set to '1' enable the HC liked reset caused by PCIe link down condition detected. If PCIe link down detected, a link down reset will always be fired to PCIe core. This field should not be modified by software.
  [18] EEPROM_LOAD_ON_MAIN rw — When set to '1' enable EEPROM reload on every main power-up This field should not be modified by software.
  [17] IGNORE_HC_RST_2PCIE_PHY rw — When set to '1' ignore HC reset to the PCIe PHY PIPE reset This field should not be modified by software.
  [16] IGNORE_MAC_PHY_PIPE_RST rw — When set to '1' ignore the LTSSM of USB link state transition caused reset to USB PHY PIPE reset This field should not be modified by software.
  [15] IGNORE_WARM_RST_4UPHY_PON rw — When set to '1' ignore warm reset of the portSC to the USB PHY power on reset This field should not be modified by software.
  [14] PCIE_LINKDOWN_RST_EN rw — When set to '1' allow PCIe link down to cause a reset to the rest of the core as the HC reset would. This field should not be modified by software.
  [13] IGNORE_HOT_RST_4U3PORT rw — When set to '1' ignore hot reset to the USB3 port logic This field should not be modified by software.
  [12] IGNORE_WARM_RST_4U3PORT rw — When set to '1' ignore warm reset to the USB3 port logic This field should not be modified by software.
  [11] IGNORE_MAIN_PWRUP_4U3PORT rw — When set to '1' ignore main power up reset to USB3 port logic This field should not be modified by software.
  [10] IGNORE_MAIN_PWRUP_4U2PORT rw — When set to '1' ignore main power up reset to USB2 port logic This field should not be modified by software.
  [9] IGNORE_MAIN_PWRUP_2PCORE rw — When set to '1' ignore main power up reset to PCIe core This field should not be modified by software.
  [8] IGNORE_MAIN_PWRUP_2PCIE_PHY rw — When set to '1' ignore main power up reset to PCIe PHY This field should not be modified by software.
  [7] IGNORE_HC_WARM_RST_2USB_PHY rw — When set to '1' ignore HC reset to the USB PHY This field should not be modified by software.
  [6] IGNORE_WARM_RST_2USB_PHY rw — When set to '1' ignore warm reset to the USB PHY This field should not be modified by software.
  [5] IGNORE_MAIN_PWRUP_RST rw — When set to '1', it enables the reset isolation function that we have added during HC reset or Per port reset. This field should not be modified by software.
  [4] PM_CTRL_MAIN_RST_EN rw — When set to '1' allow main power off condition to trigger a main power domain reset This field should not be modified by software.
  [3] IGNORE_PERST_4MAIN_PWRUP rw — When set to '1' ignore waiting for PERST# deassertion during main power show down. This field should not be modified by software.
  [2] IGNORE_PERST_4FD_RST rw — When fundamental reset is asserted during AUX power up, if this bit is set, then we will ignore PERST# such that purely wait for timeout to deassert fundamental reset. This field should not be modified by software.
  [1:0] FORCE_FD_RST rw — Writing to this field a value of 2'b11 will cause a fundamental reset. The only valid write values are 2'b11 or 2'b00 This field should not be modified by software.
